# YTM32B1MD1 register map
Vendor: YTMicro; File version: 1.4
CPU: CM33 r0p4, little endian, MPU, FPU, 2 interrupt priority bits
Registers are 32-bit, read-write, reset 0x0 unless marked. A register's access mark holds for its fields unless they carry their own. Offsets are from the block's base; [hi:lo] are bit positions; 'fields as' and 'values as' point back to an identical list.

## EFM — Embedded Flash Module
Base 0x40010000; register names take the prefix EFM_
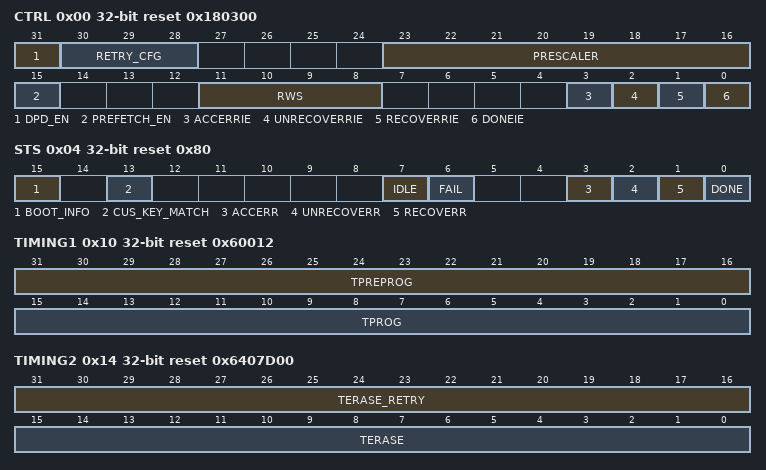
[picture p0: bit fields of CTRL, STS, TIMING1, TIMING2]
0x00 CTRL reset 0x180300
  [31] DPD_EN — This DPD_EN bit determines whether the Flash will enter deep power-down mode when MCU is entering Deepsleep mode.
    0=Flash will stay active when MCU enters Deepsleep mode; 1=Flash will enter deep power-down mode when MCU enters Deepsleep mode
  [30:28] RETRY_CFG — These RETRY_CFG bits are used for selecting one of four Erase Retry Voltage Level. 0x4: 1st erase retry pulse 0x5: 2nd erase retry pulse 0x6: 3rd erase retry pulse 0x7: 4th - 20th erase retry pulse
  [23:16] PRESCALER — These PRESCALER bits are used for EFM operation timing control. ewline These bits need to be programmed to half of core frequency. ewline Please use the following equation to calculate the PRESCALER value: ewline PRESCALER = core frequency / 2. ewline Please note that once the core frequency is changed, this field needs to be set to the appropriate value.
  [15] PREFETCH_EN — This PREFETCH_EN bit is used for enabling prefetch read functionality.
  [11:8] RWS
  [3] ACCERRIE — This ACCERRIE bit determines whether the interrupt will be generated if ACCERR flag is asserted.
    0=Disable generating interrupt if ACCERR flag is asserted; 1=Enable generating interrupt if ACCERR flag is asserted
  [2] UNRECOVERRIE — This UNRECOVERRIE bit determines whether the interrupt will be generated if UNRECOVERR flag is asserted.
    0=Disable generating interrupt if UNRECOVERR flag is asserted; 1=Enable generating interrupt if UNRECOVERR flag is asserted
  [1] RECOVERRIE — This RECOVERRIE bit determines whether the interrupt will be generated if RECOVERR flag is asserted.
    0=Disable generating interrupt if RECOVERR flag is asserted; 1=Enable generating interrupt if RECOVERR flag is asserted
  [0] DONEIE — This DONEIE bit determines whether the interrupt will be generated if DONE flag is asserted.
    0=Disable generating interrupt if DONE flag is asserted; 1=Enable generating interrupt if DONE flag is asserted
0x04 STS reset 0x80
  [15] BOOT_INFO ro — This BOOT_INFO bit indicates whether Flash SoC address remap is enabled. ewline This register bit is reset by System Reset.
    0=Flash SoC address remap is disabled, SoC boots from flash A side; 1=Flash SoC address remap is enabled, SoC boots from flash B side
  [13] CUS_KEY_MATCH ro — This CUS_KEY_MATCH bit indicates whether Customer Key is matched.
    0=Customer Key is not matched; 1=Customer Key is matched
  [7] IDLE ro — This IDLE bit indicates whether Flash is executing a command.
    0=Flash is currently executing a command; 1=No command is currently being executed
  [6] FAIL — This FAIL bit indicates whether the current command is failed. ewline Command fail includes below scenarios: ewline 1.Target program address is not erased. ewline 2.Program verify is failed. ewline 3.Erase verify is failed.
    0=Current command is succeeds; 1=Current command is fails
  [3] ACCERR — This ACCERR bit indicates whether an access error been detected. ewline Accerr error includes below scenarios: ewline 1.Access Flash when IDLE is de-asserted. ewline 2.Launch a new command when IDLE is de-asserted. ewline 3.Lack of address or data information before launching the program or erase command.
    0=Access error is not detected; 1=Access error is detected
  [2] UNRECOVERR — This UNRECOVERR bit indicates whether a 2-bit ECC error been detected.
    0=No unrecovery ECC error; 1=2-bit ECC error or multi-bit ECC error
  [1] RECOVERR — This RECOVERR bit indicates whether a 1-bit ECC error been detected.
    0=Recovery ecc error is not detected; 1=1-bit ECC error is detected
  [0] DONE — This DONE bit indicates whether the current command is completed.
    0=Current command is in progress; 1=Current command is completed
0x08 CMD
  [7:0] CMD — These CMD bits determine which commands are available.
    2=Program 64bits; 3=Program 64bits and then verify; 16=Erase sector; 17=Erase sector and then verify; 18=Erase block (only main array); 19=Erase block and then verify (only main array); 32=Load HCU Key; 48=Boot Swap; 64=Program NVR; 65=Erase NVR; 66=Read NVR
0x10 TIMING1 reset 0x60012
  [31:16] TPREPROG — These TPREPROG bits indicate the pre-program time, and the time unit is 0.5us. Please use the following equation to calculate TPREPROG value: TPREPROG = (2.5 to 3.5) * 2
  [15:0] TPROG — These TPROG bits indicate the program time, and the time unit is 0.5us. Please use the following equation to calculate TPROG value: TPROG = (8 to 10) * 2
0x14 TIMING2 reset 0x6407D00
  [31:16] TERASE_RETRY — These TERASE_RETRY bits indicate the erase-retry time, and the time unit is 0.5us. Please use the following equation to calculate TERASE_RETRY value: TERASE = (0.8 to 1) * 1000 * 2 Please note that both erase-retry is only for main array sector erase.
  [15:0] TERASE — These TERASE bits indicate the erase time, and the time unit is 0.5us. Please use the following equation to calculate TERASE value: TERASE = (16 to 20) * 1000 * 2 Please note that both sector erase (not includes erase-retry) and chip erase got the same erase time.
0x18 NVR_ADDR
  [31:0] NVR_ADDR — NVR Access Address
0x1C NVR_DATA0
  [31:0] EFM_NVR_DATA — NVR Access data
0x20 NVR_DATA1
  [31:0] EFM_NVR_DATA — NVR Access data
0x24 ADDR_PROT0 reset 0xFFFFFFFF
  [31:0] ADDR_PROT — Each bit protects 8K bytes address area. ewline if the bit is set to 0, the corresponding 8K area is under protection.
0x28 ADDR_PROT1 reset 0xFFFFFFFF
  fields as ADDR_PROT0
0x30 ERR_ADDR
  [31:0] ECC_ERR_ADDR — These bits indicates the current address of Unrecovery Ecc Error
0x200 CMD_UNLOCK
  [31:0] CMD_UNLOCK_KEY wo — Please write 0xfd9573f5 before launching any command
0x204 CUS_KEY
  [23:0] CUS_KEY wo — Please write Customer Key (default is 0x4dff32) before any protected NVR operation
0x300 CTRL_OVRD
  [1] DBG_DISABLE — This bit determines whether the debugger is override disabled.
    0=Debugger is not override disabled; 1=Debugger is override disabled

## Notices in the file
YTMicro Microcontroller all rights reserved.
